# STM32L562 register map
File version: 1.0
CPU: CM33 r0p1, little endian, MPU, FPU, 3 interrupt priority bits
Registers are 32-bit, read-write, reset 0x0 unless marked. A register's access mark holds for its fields unless they carry their own. Offsets are from the block's base; [hi:lo] are bit positions; {n}, {i} and the like mark numbered series.

## LPTIM1 — Low power timer
Base 0x40007C00
Same registers: LPTIM2 0x40009400, LPTIM3 0x40009800, SEC_LPTIM1 0x50007C00, SEC_LPTIM2 0x50009400, SEC_LPTIM3 0x50009800
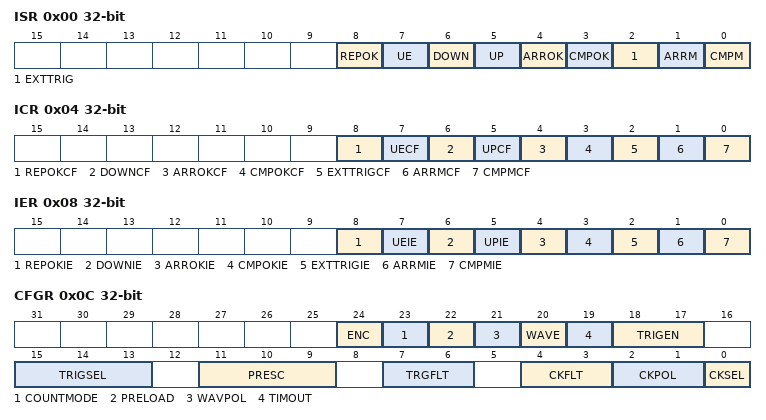
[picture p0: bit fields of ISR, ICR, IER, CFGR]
0x00 ISR ro — Interrupt and Status Register
  [8] REPOK — Repetition register update Ok
    1=Set (Repetition register update OK)
  [7] UE — LPTIM update event occurred
    1=Set (LPTIM update event occurred)
  [6] DOWN — Counter direction change up to down
    1=Set (Counter direction change up to down)
  [5] UP — Counter direction change down to up
    1=Set (Counter direction change down to up)
  [4] ARROK — Autoreload register update OK
    1=Set (Autoreload register update OK)
  [3] CMPOK — Compare register update OK
    1=Set (Compare register update OK)
  [2] EXTTRIG — External trigger edge event
    1=Set (External trigger edge event)
  [1] ARRM — Autoreload match
    1=Set (Autoreload match)
  [0] CMPM — Compare match
    1=Set (Compare match)
0x04 ICR wo — Interrupt Clear Register
  [8] REPOKCF — Repetition register update OK clear flag
    1=Clear REPOK flag
  [7] UECF — Update event clear flag
    1=Clear update event flag
  [6] DOWNCF — Direction change to down Clear Flag
    1=Clear (Direction change to down Clear Flag)
  [5] UPCF — Direction change to UP Clear Flag
    1=Clear (Direction change to up Clear Flag)
  [4] ARROKCF — Autoreload register update OK Clear Flag
    1=Clear (Autoreload register update OK Clear Flag)
  [3] CMPOKCF — Compare register update OK Clear Flag
    1=Clear (Compare register update OK Clear Flag)
  [2] EXTTRIGCF — External trigger valid edge Clear Flag
    1=Clear (External trigger valid edge Clear Flag)
  [1] ARRMCF — Autoreload match Clear Flag
    1=Clear (Autoreload match Clear Flag)
  [0] CMPMCF — compare match Clear Flag
    1=Clear (Compare match Clear Flag)
0x08 IER — Interrupt Enable Register
  [8] REPOKIE
    0=Disabled (Repetition register update OK interrupt disabled); 1=Enabled (Repetition register update OK interrupt enabled)
  [7] UEIE — Update event interrupt enable
    0=Disabled (Update event interrupt disabled); 1=Enabled (Update event interrupt enabled)
  [6] DOWNIE — Direction change to down Interrupt Enable
    0=Disabled (DOWN interrupt disabled); 1=Enabled (DOWN interrupt enabled)
  [5] UPIE — Direction change to UP Interrupt Enable
    0=Disabled (UP interrupt disabled); 1=Enabled (UP interrupt enabled)
  [4] ARROKIE — Autoreload register update OK Interrupt Enable
    0=Disabled (ARROK interrupt disabled); 1=Enabled (ARROK interrupt enabled)
  [3] CMPOKIE — Compare register update OK Interrupt Enable
    0=Disabled (CMPOK interrupt disabled); 1=Enabled (CMPOK interrupt enabled)
  [2] EXTTRIGIE — External trigger valid edge Interrupt Enable
    0=Disabled (EXTTRIG interrupt disabled); 1=Enabled (EXTTRIG interrupt enabled)
  [1] ARRMIE — Autoreload match Interrupt Enable
    0=Disabled (ARRM interrupt disabled); 1=Enabled (ARRM interrupt enabled)
  [0] CMPMIE — Compare match Interrupt Enable
    0=Disabled (CMPM interrupt disabled); 1=Enabled (CMPM interrupt enabled)
0x0C CFGR — Configuration Register
  [24] ENC — Encoder mode enable
    0=Disabled (Encoder mode disabled); 1=Enabled (Encoder mode enabled)
  [23] COUNTMODE — counter mode enabled
    0=Internal (The counter is incremented following each internal clock pulse); 1=External (The counter is incremented following each valid clock pulse on the LPTIM external Input1)
  [22] PRELOAD — Registers update mode
    0=Immediate (Registers are updated after each APB bus write access); 1=EndOfPeriod (Registers are updated at the end of the current LPTIM period)
  [21] WAVPOL — Waveform shape polarity
    0=Positive (The LPTIM output reflects the compare results between LPTIM_ARR and LPTIM_CMP registers); 1=Negative (The LPTIM output reflects the inverse of the compare results between LPTIM_ARR and LPTIM_CMP registers)
  [20] WAVE — Waveform shape
    0=Inactive (Deactivate Set-once mode, PWM / One Pulse waveform (depending on OPMODE bit)); 1=Active (Activate the Set-once mode)
  [19] TIMOUT — Timeout enable
    0=Disabled (A trigger event arriving when the timer is already started will be ignored); 1=Enabled (A trigger event arriving when the timer is already started will reset and restart the counter)
  [18:17] TRIGEN — Trigger enable and polarity
    0=SW (Software trigger (counting start is initiated by software)); 1=Rising edge is the active edge; 2=Falling edge is the active edge; 3=Both edges are active edges
  [15:13] TRIGSEL — Trigger selector
    {v}=Trig{v} (lptim_ext_trig{v}) (v=0..7)
  [11:9] PRESC — Clock prescaler
    0=Div1 (/1); 1=Div2 (/2); 2=Div4 (/4); 3=Div8 (/8); 4=Div16 (/16); 5=Div32 (/32); 6=Div64 (/64); 7=Div128 (/128)
  [7:6] TRGFLT — Configurable digital filter for trigger
    0=Immediate (Any trigger active level change is considered as a valid trigger); 1=Clocks2 (Trigger active level change must be stable for at least 2 clock periods before it is considered as valid trigger); 2=Clocks4 (Trigger active level change must be stable for at least 4 clock periods before it is considered as valid trigger); 3=Clocks8 (Trigger active level change must be stable for at least 8 clock periods before it is considered as valid trigger)
  [4:3] CKFLT — Configurable digital filter for external clock
    0=Immediate (Any external clock signal level change is considered as a valid transition); 1=Clocks2 (External clock signal level change must be stable for at least 2 clock periods before it is considered as valid transition); 2=Clocks4 (External clock signal level change must be stable for at least 4 clock periods before it is considered as valid transition); 3=Clocks8 (External clock signal level change must be stable for at least 8 clock periods before it is considered as valid transition)
  [2:1] CKPOL — Clock Polarity
    0=RisingEdge (The rising edge is the active edge used for counting. If LPTIM is in encoder mode: Encoder sub-mode 1 is active.); 1=FallingEdge (The falling edge is the active edge used for counting. If LPTIM is in encoder mode: Encoder sub-mode 2 is active.); 2=Both edges are active edge. If LPTIM is in encoder mode: Encoder sub-mode 3 is active.
  [0] CKSEL — Clock selector
    0=Internal (LPTIM is clocked by internal clock source (APB clock or any of the embedded oscillators)); 1=External (LPTIM is clocked by an external clock source through the LPTIM external Input1)
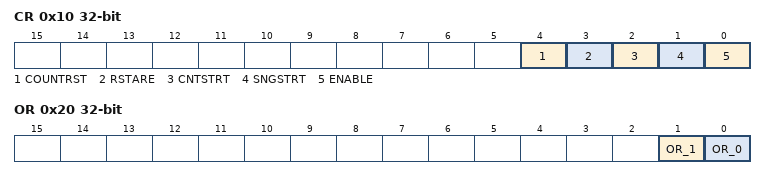
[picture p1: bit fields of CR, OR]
0x10 CR — Control Register
  [4] COUNTRST — Counter reset
    on read: 0=Idle (Triggering of reset is possible); 1=Busy (Reset in progress, do not write 1 to this field) | on write: 1=Reset (Trigger synchronous reset of CNT (3 LPTimer core clock cycles))
  [3] RSTARE — Reset after read enable
    0=Disabled (CNT Register reads do not trigger reset); 1=Enabled (CNT Register reads trigger reset of LPTIM)
  [2] CNTSTRT — Timer start in continuous mode
    on write: 1=Start (Timer start in Continuous mode)
  [1] SNGSTRT — LPTIM start in single mode
    on write: 1=Start (LPTIM start in Single mode)
  [0] ENABLE — LPTIM Enable
    0=Disabled (LPTIM is disabled); 1=Enabled (LPTIM is enabled)
0x14 CMP — Compare Register
  [15:0] CMP — Compare value
0x18 ARR reset 0x1 — Autoreload Register
  [15:0] ARR — Auto reload value
0x1C CNT ro — Counter Register
  [15:0] CNT — Counter value
0x20 OR — LPTIM option register
  [1] OR_1 — Option register bit 1
  [0] OR_0 — Option register bit 0
0x28 RCR — LPTIM repetition register
  [7:0] REP — Repetition register value
